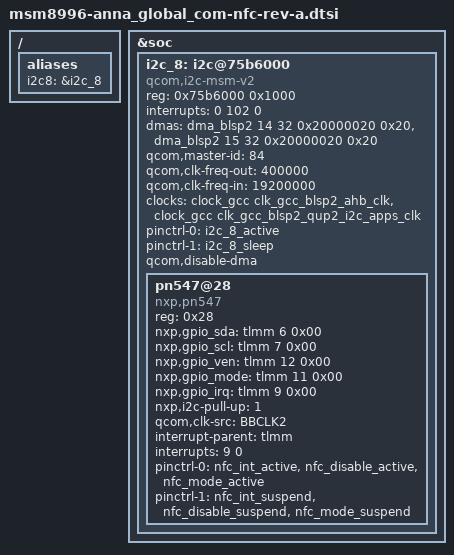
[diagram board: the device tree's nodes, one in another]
/* Copyright (c) 2012, Code Aurora Forum. All rights reserved.
 *
 * This program is free software; you can redistribute it and/or modify
 * it under the terms of the GNU General Public License version 2 and
 * only version 2 as published by the Free Software Foundation.
 *
 * This program is distributed in the hope that it will be useful,
 * but WITHOUT ANY WARRANTY; without even the implied warranty of
 * MERCHANTABILITY or FITNESS FOR A PARTICULAR PURPOSE.  See the
 * GNU General Public License for more details.
 */

/ {
	aliases {
		i2c8 = &i2c_8;
	};
};

&soc{
	i2c_8: i2c@75b6000 { /* BLSP2 QUP1 */
		compatible = "qcom,i2c-msm-v2";
		#address-cells = <1>;
		#size-cells = <0>;
		reg-names = "qup_phys_addr";
		reg = <0x75b6000 0x1000>;
		interrupt-names = "qup_irq";
		interrupts = <0 102 0>;
		dmas = <&dma_blsp2 14 32 0x20000020 0x20>,
			<&dma_blsp2 15 32 0x20000020 0x20>;
		dma-names = "tx", "rx";
		qcom,master-id = <84>;
		qcom,clk-freq-out = <400000>;
		qcom,clk-freq-in  = <19200000>;
		clock-names = "iface_clk", "core_clk";
		clocks = <&clock_gcc clk_gcc_blsp2_ahb_clk>,
			 <&clock_gcc clk_gcc_blsp2_qup2_i2c_apps_clk>;
		pinctrl-names = "i2c_active", "i2c_sleep";
		pinctrl-0 = <&i2c_8_active>;
		pinctrl-1 = <&i2c_8_sleep>;
		qcom,disable-dma;
	};
};

&i2c_8 {
	qcom,clk-freq-out = <400000>;
	pn547@28 {
		compatible = "nxp,pn547";
		reg = <0x28>;
		status = "ok";
		nxp,gpio_sda = <&tlmm 6 0x00>;
		nxp,gpio_scl = <&tlmm 7 0x00>;
		nxp,gpio_ven = <&tlmm 12 0x00>;
		nxp,gpio_mode = <&tlmm 11 0x00>;
		nxp,gpio_irq = <&tlmm 9 0x00>;
		nxp,i2c-pull-up = <1>;
		qcom,clk-src = "BBCLK2";
		interrupt-parent = <&tlmm>;
		interrupts = <9 0>;
		interrupt-names = "nfc_irq";
		pinctrl-names = "nfc_active","nfc_suspend";
		pinctrl-0 = <&nfc_int_active &nfc_disable_active &nfc_mode_active>;
		pinctrl-1 = <&nfc_int_suspend &nfc_disable_suspend &nfc_mode_suspend>;
		//qcom,clk-gpio = <&pm8994_gpios 10 0>;
		//clock-names = "pin_clk", "cont_clk";
		//clocks = <&clock_rpm clk_bb_clk2_pin>,
		//	<&clock_rpm clk_bb_clk2>;
	};
};
